# haltium_secure register map
Vendor: Nordic Semiconductor; Series: nRFHaltium; File version: 1
CPU: CM33 r0p4, little endian, MPU, FPU, 3 interrupt priority bits, 480 interrupts
Registers are 32-bit, read-write, reset 0x0 unless marked. A register's access mark holds for its fields unless they carry their own. Offsets are from the block's base; [hi:lo] are bit positions; lines under a group give offsets from that group; {n}, {i} and the like mark numbered series.

## GSPU14_S — System protection unit 0
Base 0xBF000000
Same registers: SPU0_S 0x51000000, SPU1_S 0x51010000, GSPU0_S 0x5F080000, GSPU1_S 0x5F090000, GSPU2_S 0x5F8C0000, GSPU3_S 0x5F8D0000, GSPU4_S 0x5F8E0000, GSPU5_S 0x5F900000, GSPU6_S 0x5F920000, GSPU7_S 0x5F940000, GSPU8_S 0x5F980000, GSPU9_S 0x5F990000, GSPU10_S 0x5F9A0000, GSPU11_S 0x5F9B0000, GSPU12_S 0x5F9C0000, GSPU13_S 0x5F9D0000
0x100 EVENTS_PERIPHACCERR — A security violation has been detected on one or several peripherals
  [0] EVENTS_PERIPHACCERR
    0=NotGenerated (Event not generated); 1=Generated (Event generated)
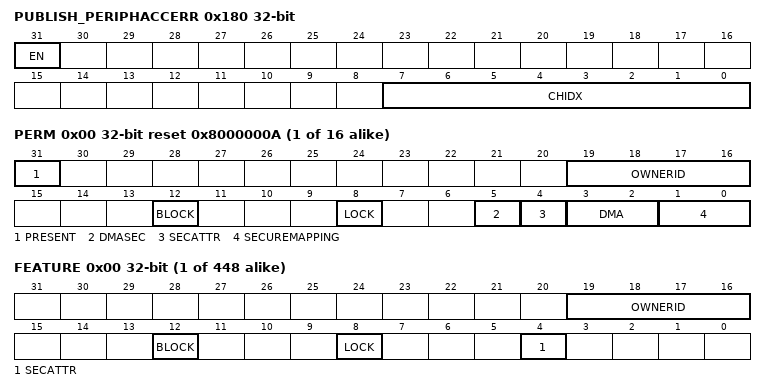
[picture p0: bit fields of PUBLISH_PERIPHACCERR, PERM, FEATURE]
0x180 PUBLISH_PERIPHACCERR — Publish configuration for event PERIPHACCERR
  [31] EN
    0=Disabled (Disable publishing); 1=Enabled (Enable publishing)
  [7:0] CHIDX — DPPI channel that event PERIPHACCERR will publish to
0x300 INTEN — Enable or disable interrupt
  [0] PERIPHACCERR — Enable or disable interrupt for event PERIPHACCERR
    0=Disabled; 1=Enabled
0x304 INTENSET — Enable interrupt
  [0] PERIPHACCERR — Write '1' to enable interrupt for event PERIPHACCERR
    on read: 0=Disabled (Read: Disabled); 1=Enabled (Read: Enabled) | on write: 1=Set (Enable)
0x308 INTENCLR — Disable interrupt
  [0] PERIPHACCERR — Write '1' to disable interrupt for event PERIPHACCERR
    on read: 0=Disabled (Read: Disabled); 1=Enabled (Read: Enabled) | on write: 1=Clear (Disable)
0x400 CAP ro reset 0x1 — Show implemented features for the current device
  [0] TZM — Show ARM TrustZone status
    0=NotAvailable (ARM TrustZone support not available); 1=Enabled (ARM TrustZone support is available)
0x404 PERIPHACCERR group — Information related to PERIPHACCERR event
  0x00 ADDRESS ro reset 0x8001 — PEPERIPHACCERR event address
  0x04 INFO ro reset 0x8001 — PEPERIPHACCERR event OWNERID info
    [3:0] INFO
{0x500+4i} PERIPHID[{i}] (i=0..15) group — Unspecified
  0x00 PERM reset 0x8000000A — Description cluster: List capabilities and access permissions for the peripheral with ID n
    [31] PRESENT ro — Indicate if a peripheral is present with ID n
      0=NotPresent (Peripheral is not present); 1=IsPresent (Peripheral is present)
    [19:16] OWNERID — Peripheral owner ID
    [12] BLOCK write-once — Peripheral block
      0=Available (Peripheral is accessible); 1=Blocked (Peripheral cannot be accessed until next reset)
    [8] LOCK
      0=Unlocked (This register can be updated); 1=Locked (The content of this register can not be changed until the next reset)
    [5] DMASEC — Security attribution for the DMA transfer
      1=Secure (DMA transfers initiated by this peripheral have the secure attribute set); 0=NonSecure (DMA transfers initiated by this peripheral have the non-secure attribute set)
    [4] SECATTR — Peripheral security mapping
      1=Secure (Peripheral is mapped in secure peripheral address space); 0=NonSecure (If SECUREMAPPING == UserSelectable: Peripheral is mapped in non-secure peripheral address space. If SECUREMAPPING == Split: Peripheral is mapped in non-secure and secure peripheral address space.)
    [3:2] DMA ro — Indicate if the peripheral has DMA capabilities and if DMA transfer can be assigned to a different security attribute than the peripheral itself
      0=NoDMA (Peripheral has no DMA capability); 1=NoSeparateAttribute (Peripheral has DMA and DMA transfers always have the same security attribute as assigned to the peripheral); 2=SeparateAttribute (Peripheral has DMA and DMA transfers can have a different security attribute than the one assigned to the peripheral)
    [1:0] SECUREMAPPING ro — Define configuration capabilities for TrustZone Cortex-M secure attribute
      0=NonSecure (This peripheral is always accessible as a non-secure peripheral); 1=Secure (This peripheral is always accessible as a secure peripheral); 2=UserSelectable (Non-secure or secure attribute for this peripheral is defined by the PERIPHID[n].PERM register); 3=Split (This peripheral implements the split security mechanism. Non-secure or secure attribute for this peripheral is defined by the PERIPHID[n].PERM register.)
{0x800+4i} FEATURE[{i}] (i=0..447) group — Unspecified
  0x00 FEATURE — Description cluster: List features of FEATURE n
    [19:16] OWNERID — Feature owner ID
    [12] BLOCK — BLOCK feature
      0=Available (Feature is accessible); 1=Blocked (Feature cannot be accessed until next reset)
    [8] LOCK — LOCK feature
      0=Unlocked (Feature permissions can be updated); 1=Locked (Feature permissions can not be changed until the next reset)
    [4] SECATTR — SECATTR feature
      0=NonSecure (Feature is availabe for non-secure usage); 1=Secure (Feature is reserved for secure usage)
